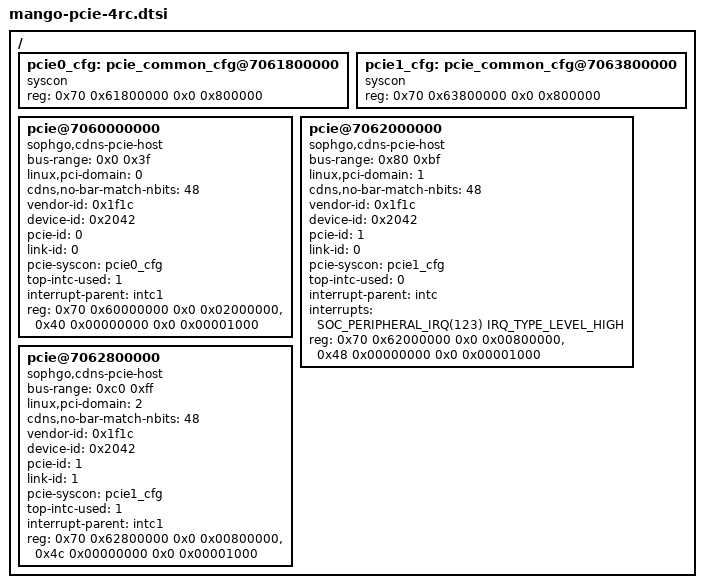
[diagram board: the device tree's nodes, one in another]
#include <dt-bindings/interrupt-controller/irq.h>

#define SOC_PERIPHERAL_IRQ(nr)	(nr)

/ {
	pcie0_cfg: pcie_common_cfg@7061800000 {
		compatible = "syscon";
		reg = <0x70 0x61800000 0x0 0x800000>;
	};

	pcie1_cfg: pcie_common_cfg@7063800000 {
		compatible = "syscon";
		reg = <0x70 0x63800000 0x0 0x800000>;
	};

	pcie@7060000000 {
		compatible = "sophgo,cdns-pcie-host";
		device_type = "pci";
		#address-cells = <3>;
		#size-cells = <2>;

		bus-range = <0x0 0x3f>;
		linux,pci-domain = <0>;
		cdns,no-bar-match-nbits = <48>;
		vendor-id = <0x1f1c>;
		device-id = <0x2042>;
		pcie-id = <0>;
		link-id = <0>;
		pcie-syscon = <&pcie0_cfg>;
		top-intc-used = <1>;
		interrupt-parent = <&intc1>;
		//top-intc-used = <0>;
		//interrupt-parent = <&intc>;
		//interrupts = <SOC_PERIPHERAL_IRQ(122) IRQ_TYPE_LEVEL_HIGH>;
		//interrupt-names = "msi";
		reg = <0x70 0x60000000  0x0 0x02000000>,
		      <0x40 0x00000000  0x0 0x00001000>;
		reg-names = "reg", "cfg";

		// IO, check IO_SPACE_LIMIT
		// 32bit prefetchable memory
		// 32bit non-prefetchable memory
		// 64bit prefetchable memory
		// 64bit non-prefetchable memory
		ranges = <0x01000000 0x0  0xc0000000  0x40 0xc0000000  0x0 0x00400000>,
			 <0x42000000 0x0  0xd0000000  0x40 0xd0000000  0x0 0x10000000>,
			 <0x02000000 0x0  0xe0000000  0x40 0xe0000000  0x0 0x20000000>,
			 <0x43000000 0x42 0x00000000  0x42 0x00000000  0x2 0x00000000>,
			 <0x03000000 0x41 0x00000000  0x41 0x00000000  0x1 0x00000000>;

		status = "okay";
	};

	pcie@7062000000 {
		compatible = "sophgo,cdns-pcie-host";
		device_type = "pci";
		#address-cells = <3>;
		#size-cells = <2>;

		bus-range = <0x80 0xbf>;
		linux,pci-domain = <1>;
		cdns,no-bar-match-nbits = <48>;
		vendor-id = <0x1f1c>;
		device-id = <0x2042>;
		pcie-id = <1>;
		link-id = <0>;
		pcie-syscon = <&pcie1_cfg>;
		top-intc-used = <0>;
		interrupt-parent = <&intc>;
		interrupts = <SOC_PERIPHERAL_IRQ(123) IRQ_TYPE_LEVEL_HIGH>;
		interrupt-names = "msi";
		reg = <0x70 0x62000000  0x0 0x00800000>,
		      <0x48 0x00000000  0x0 0x00001000>;
		reg-names = "reg", "cfg";

		// IO, check IO_SPACE_LIMIT
		// 32bit prefetchable memory
		// 32bit non-prefetchable memory
		// 64bit prefetchable memory
		// 64bit non-prefetchable memory
		ranges = <0x01000000 0x0  0xc0800000  0x48 0xc0800000  0x0 0x00400000>,
			 <0x42000000 0x0  0xd0000000  0x48 0xd0000000  0x0 0x10000000>,
			 <0x02000000 0x0  0xe0000000  0x48 0xe0000000  0x0 0x20000000>,
			 <0x03000000 0x49 0x00000000  0x49 0x00000000  0x1 0x00000000>,
			 <0x43000000 0x4a 0x00000000  0x4a 0x00000000  0x2 0x00000000>;

		status = "okay";
	};

	pcie@7062800000 {
		compatible = "sophgo,cdns-pcie-host";
		device_type = "pci";
		#address-cells = <3>;
		#size-cells = <2>;

		bus-range = <0xc0 0xff>;
		linux,pci-domain = <2>;
		cdns,no-bar-match-nbits = <48>;
		vendor-id = <0x1f1c>;
		device-id = <0x2042>;
		pcie-id = <1>;
		link-id = <1>;
		pcie-syscon = <&pcie1_cfg>;
		top-intc-used = <1>;
		interrupt-parent = <&intc1>;
		reg = <0x70 0x62800000  0x0 0x00800000>,
		      <0x4c 0x00000000  0x0 0x00001000>;
		reg-names = "reg", "cfg";

		// IO, check IO_SPACE_LIMIT
		// 32bit prefetchable memory
		// 32bit non-prefetchable memory
		// 64bit prefetchable memory
		// 64bit non-prefetchable memory
		ranges = <0x01000000 0x0  0xc0c00000  0x4c 0xc0c00000  0x0 0x00400000>,
			 <0x42000000 0x0  0xf8000000  0x4c 0xf8000000  0x0 0x04000000>,
			 <0x02000000 0x0  0xfc000000  0x4c 0xfc000000  0x0 0x04000000>,
			 <0x43000000 0x4e 0x00000000  0x4e 0x00000000  0x2 0x00000000>,
			 <0x03000000 0x4d 0x00000000  0x4d 0x00000000  0x1 0x00000000>;

		status = "okay";
	};
};
